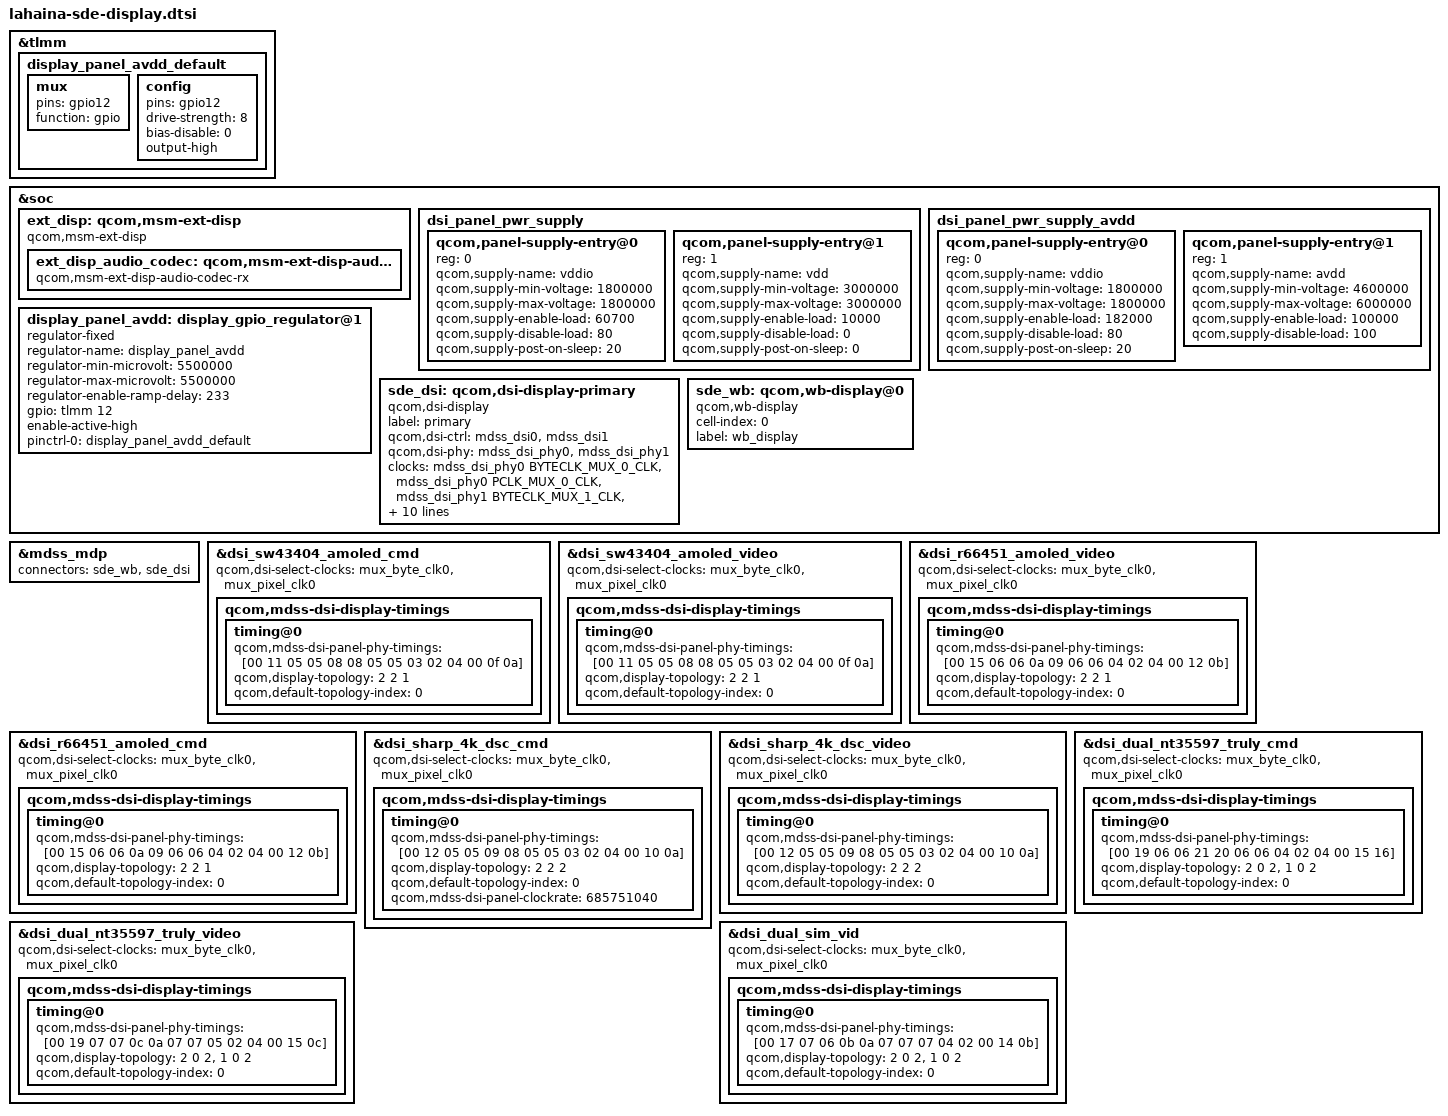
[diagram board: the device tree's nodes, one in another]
#include "dsi-panel-sw43404-amoled-dsc-wqhd-cmd.dtsi"
#include "dsi-panel-sw43404-amoled-dsc-wqhd-video.dtsi"
#include "dsi-panel-sw43404-amoled-dsc-fhd-plus-cmd.dtsi"
#include "dsi-panel-sharp-dsc-4k-cmd.dtsi"
#include "dsi-panel-sharp-dsc-4k-video.dtsi"
#include "dsi-panel-sharp-qsync-wqhd-cmd.dtsi"
#include "dsi-panel-sharp-qsync-wqhd-video.dtsi"
#include "dsi-panel-sharp-1080p-cmd.dtsi"
#include "dsi-panel-nt35597-truly-dualmipi-wqxga-cmd.dtsi"
#include "dsi-panel-nt35597-truly-dualmipi-wqxga-video.dtsi"
#include "dsi-panel-nt35695b-truly-fhd-cmd.dtsi"
#include "dsi-panel-nt35695b-truly-fhd-video.dtsi"
#include "dsi-panel-r66451-dsc-qhd-cmd.dtsi"
#include "dsi-panel-r66451-dsc-qhd-video.dtsi"
#include "dsi-panel-ext-bridge-1080p.dtsi"
#include "dsi-panel-sim-cmd.dtsi"
#include "dsi-panel-sim-video.dtsi"
#include "dsi-panel-sim-dsc375-cmd.dtsi"
#include "dsi-panel-sim-dsc-10bit-cmd.dtsi"
#include "dsi-panel-sim-dualmipi-cmd.dtsi"
#include "dsi-panel-sim-dualmipi-video.dtsi"
#include "dsi-panel-sim-dualmipi-dsc375-cmd.dtsi"
#include "dsi-panel-sim-sec-hd-cmd.dtsi"
#include <dt-bindings/clock/mdss-5nm-pll-clk.h>
#include "dsi-panel-sim-vdc-vid.dtsi"
#include "dsi-panel-sim-vdc-cmd.dtsi"

&tlmm {
	display_panel_avdd_default: display_panel_avdd_default {
		mux {
			pins = "gpio12";
			function = "gpio";
		};

		config {
			pins = "gpio12";
			drive-strength = <8>;
			bias-disable = <0>;
			output-high;
		};
	};
};

&soc {
	ext_disp: qcom,msm-ext-disp {
		compatible = "qcom,msm-ext-disp";

		ext_disp_audio_codec: qcom,msm-ext-disp-audio-codec-rx {
			compatible = "qcom,msm-ext-disp-audio-codec-rx";
		};
	};

	dsi_panel_pwr_supply: dsi_panel_pwr_supply {
		#address-cells = <1>;
		#size-cells = <0>;

		qcom,panel-supply-entry@0 {
			reg = <0>;
			qcom,supply-name = "vddio";
			qcom,supply-min-voltage = <1800000>;
			qcom,supply-max-voltage = <1800000>;
			qcom,supply-enable-load = <60700>;
			qcom,supply-disable-load = <80>;
			qcom,supply-post-on-sleep = <20>;
		};

		qcom,panel-supply-entry@1 {
			reg = <1>;
			qcom,supply-name = "vdd";
			qcom,supply-min-voltage = <3000000>;
			qcom,supply-max-voltage = <3000000>;
			qcom,supply-enable-load = <10000>;
			qcom,supply-disable-load = <0>;
			qcom,supply-post-on-sleep = <0>;
		};
	};

	dsi_panel_pwr_supply_avdd: dsi_panel_pwr_supply_avdd {
		#address-cells = <1>;
		#size-cells = <0>;

		qcom,panel-supply-entry@0 {
			reg = <0>;
			qcom,supply-name = "vddio";
			qcom,supply-min-voltage = <1800000>;
			qcom,supply-max-voltage = <1800000>;
			qcom,supply-enable-load = <182000>;
			qcom,supply-disable-load = <80>;
			qcom,supply-post-on-sleep = <20>;
		};

		qcom,panel-supply-entry@1 {
			reg = <1>;
			qcom,supply-name = "avdd";
			qcom,supply-min-voltage = <4600000>;
			qcom,supply-max-voltage = <6000000>;
			qcom,supply-enable-load = <100000>;
			qcom,supply-disable-load = <100>;
		};
	};

	display_panel_avdd: display_gpio_regulator@1 {
		compatible = "regulator-fixed";
		regulator-name = "display_panel_avdd";
		regulator-min-microvolt = <5500000>;
		regulator-max-microvolt = <5500000>;
		regulator-enable-ramp-delay = <233>;
		gpio = <&tlmm 12 0>;
		enable-active-high;
		pinctrl-names = "default";
		pinctrl-0 = <&display_panel_avdd_default>;
	};

	sde_dsi: qcom,dsi-display-primary {
		compatible = "qcom,dsi-display";
		label = "primary";

		qcom,dsi-ctrl = <&mdss_dsi0 &mdss_dsi1>;
		qcom,dsi-phy = <&mdss_dsi_phy0 &mdss_dsi_phy1>;

		clocks = <&mdss_dsi_phy0 BYTECLK_MUX_0_CLK>,
			 <&mdss_dsi_phy0 PCLK_MUX_0_CLK>,
			 <&mdss_dsi_phy1 BYTECLK_MUX_1_CLK>,
			 <&mdss_dsi_phy1 PCLK_MUX_1_CLK>;
		clock-names = "mux_byte_clk0", "mux_pixel_clk0",
			      "mux_byte_clk1", "mux_pixel_clk1";

		pinctrl-names = "panel_active", "panel_suspend";
		pinctrl-0 = <&sde_dsi_active &sde_te_active>;
		pinctrl-1 = <&sde_dsi_suspend &sde_te_suspend>;

		qcom,platform-te-gpio = <&tlmm 82 0>;
		qcom,panel-te-source = <0>;

		vddio-supply = <&L12C>;
		vdd-supply = <&L13C>;
		avdd-supply = <&display_panel_avdd>;

		qcom,mdp = <&mdss_mdp>;
		qcom,dsi-default-panel = <&dsi_sw43404_amoled_cmd>;
	};

	sde_wb: qcom,wb-display@0 {
		compatible = "qcom,wb-display";
		cell-index = <0>;
		label = "wb_display";
	};
};

&mdss_mdp {
	connectors = <&sde_wb &sde_dsi>;
};

/* PHY TIMINGS REVISION YB */
&dsi_sw43404_amoled_cmd {
	qcom,dsi-select-clocks = "mux_byte_clk0", "mux_pixel_clk0";

	qcom,mdss-dsi-display-timings {
		timing@0 {
			qcom,mdss-dsi-panel-phy-timings = [00 11 05 05 08 08 05
				05 03 02 04 00 0f 0a];
			qcom,display-topology = <2 2 1>;
			qcom,default-topology-index = <0>;
		};
	};
};

&dsi_sw43404_amoled_video {
	qcom,dsi-select-clocks = "mux_byte_clk0", "mux_pixel_clk0";

	qcom,mdss-dsi-display-timings {
		timing@0 {
			qcom,mdss-dsi-panel-phy-timings = [00 11 05 05 08 08 05
				05 03 02 04 00 0f 0a];
			qcom,display-topology = <2 2 1>;
			qcom,default-topology-index = <0>;
		};
	};
};

&dsi_r66451_amoled_video {
	qcom,dsi-select-clocks = "mux_byte_clk0", "mux_pixel_clk0";
	qcom,mdss-dsi-display-timings {
		timing@0 {
			qcom,mdss-dsi-panel-phy-timings = [00 15 06 06 0a 09 06
				06 04 02 04 00 12 0b];
			qcom,display-topology = <2 2 1>;
			qcom,default-topology-index = <0>;
		};
	};
};

&dsi_r66451_amoled_cmd {
	qcom,dsi-select-clocks = "mux_byte_clk0", "mux_pixel_clk0";
	qcom,mdss-dsi-display-timings {
		timing@0 {
			qcom,mdss-dsi-panel-phy-timings = [00 15 06 06 0a 09 06
				06 04 02 04 00 12 0b];
			qcom,display-topology = <2 2 1>;
			qcom,default-topology-index = <0>;
		};
	};
};

&dsi_sharp_4k_dsc_cmd {
	qcom,dsi-select-clocks = "mux_byte_clk0", "mux_pixel_clk0";
	qcom,mdss-dsi-display-timings {
		timing@0 {
			qcom,mdss-dsi-panel-phy-timings = [00 12 05 05 09 08 05
				05 03 02 04 00 10 0a];
			qcom,display-topology = <2 2 2>;
			qcom,default-topology-index = <0>;
			/*
			 * Using same clock as Video mode panel as a
			 * temporary solution for PHY timing issue that causes
			 * corruption.
			 */
			qcom,mdss-dsi-panel-clockrate = <685751040>;
		};
	};
};

&dsi_sharp_4k_dsc_video {
	qcom,dsi-select-clocks = "mux_byte_clk0", "mux_pixel_clk0";
	qcom,mdss-dsi-display-timings {
		timing@0 {
			qcom,mdss-dsi-panel-phy-timings = [00 12 05 05 09 08 05
				05 03 02 04 00 10 0a];
			qcom,display-topology = <2 2 2>;
			qcom,default-topology-index = <0>;
		};
	};
};

&dsi_dual_nt35597_truly_cmd {
	qcom,dsi-select-clocks = "mux_byte_clk0", "mux_pixel_clk0";
	qcom,mdss-dsi-display-timings {
		timing@0 {
			/*
			 * Using PHY Timings version W as a
			 * temporary solution for PHY timing issue that causes
			 * corruption.
			 */
			qcom,mdss-dsi-panel-phy-timings = [00 19 06 06 21 20 06
				06 04 02 04 00 15 16];
			qcom,display-topology = <2 0 2>,
						<1 0 2>;
			qcom,default-topology-index = <0>;
		};
	};
};

&dsi_dual_nt35597_truly_video {
	qcom,dsi-select-clocks = "mux_byte_clk0", "mux_pixel_clk0";
	qcom,mdss-dsi-display-timings {
		timing@0 {
			qcom,mdss-dsi-panel-phy-timings = [00 19 07 07 0c 0a 07
				07 05 02 04 00 15 0c];
			qcom,display-topology = <2 0 2>,
						<1 0 2>;
			qcom,default-topology-index = <0>;
		};
	};
};

&dsi_dual_sim_vid {
	qcom,dsi-select-clocks = "mux_byte_clk0", "mux_pixel_clk0";
	qcom,mdss-dsi-display-timings {
		timing@0 {
			qcom,mdss-dsi-panel-phy-timings = [00 17 07 06 0b 0a 07
				07 07 04 02 00 14 0b];
			qcom,display-topology = <2 0 2>,
						<1 0 2>;
			qcom,default-topology-index = <0>;
		};
	};
};
